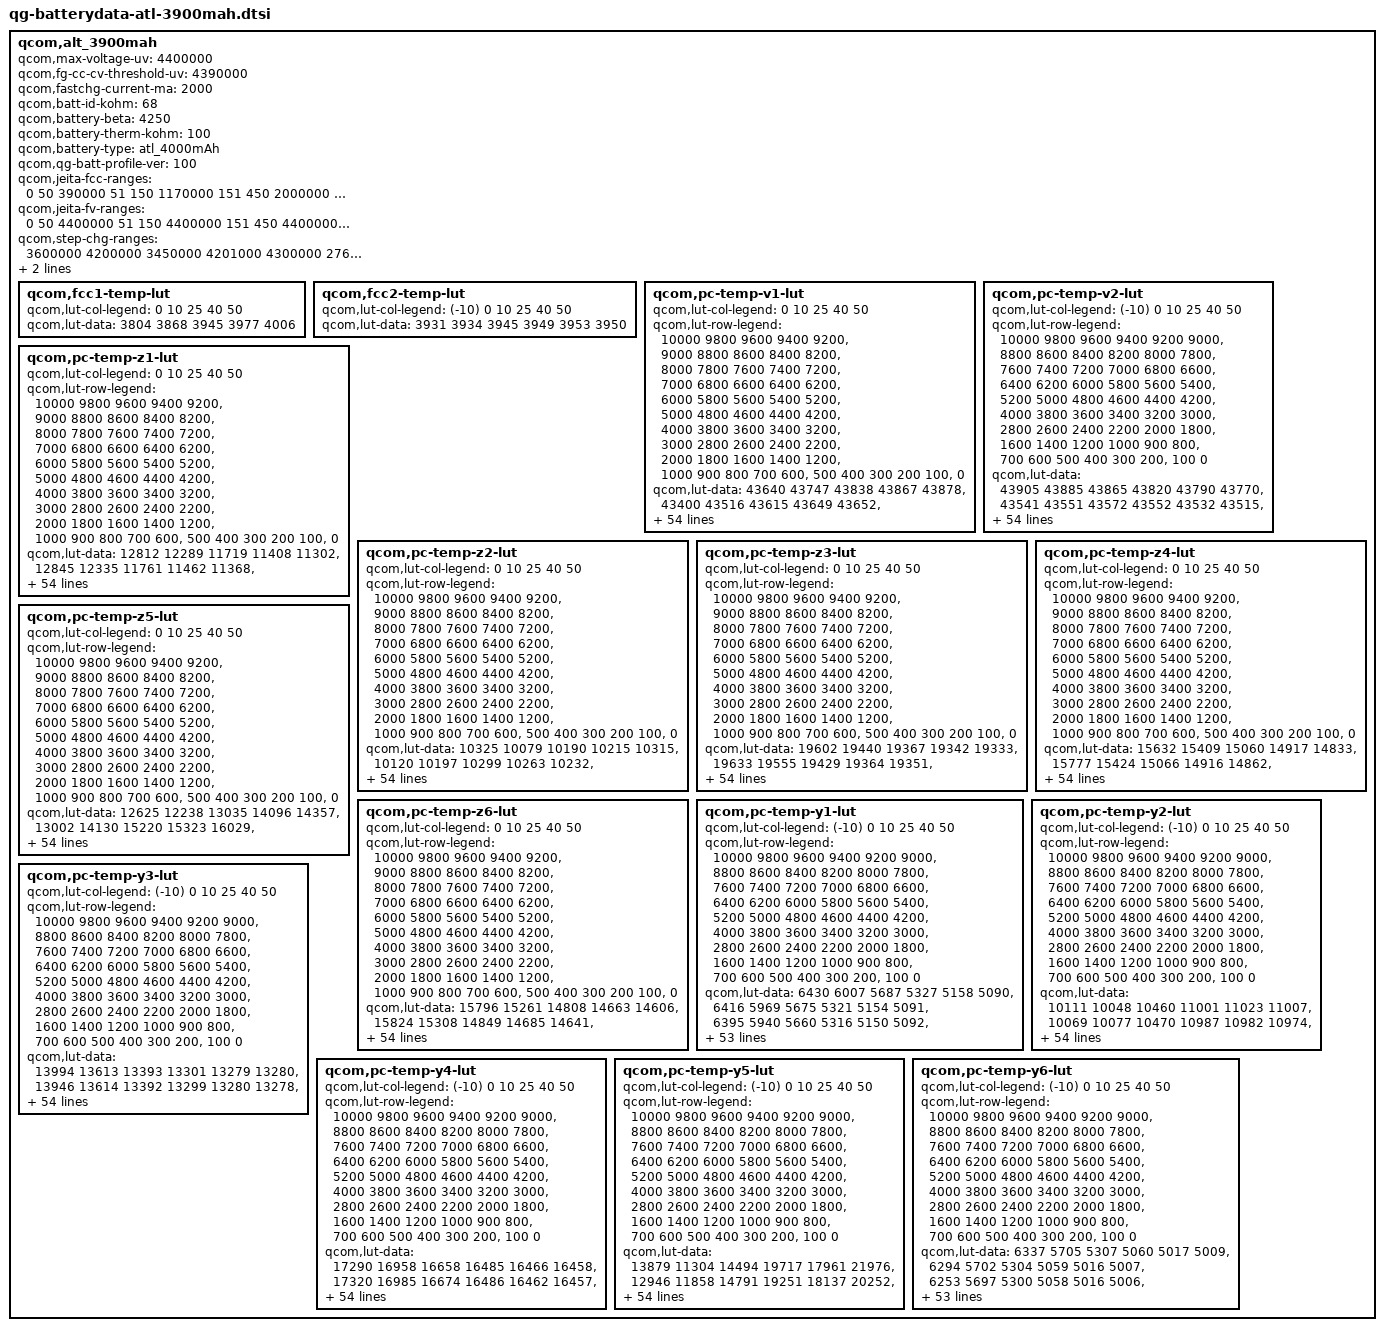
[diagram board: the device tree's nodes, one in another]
qcom,alt_3900mah {
    /* 3668667_LC_M5100_ATL_4000mAH_FG_averaged_MasterSlave_Nov3rd2018 */
    qcom,max-voltage-uv = <4400000>;
    qcom,fg-cc-cv-threshold-uv = <4390000>;
    qcom,fastchg-current-ma = <2000>;
    qcom,batt-id-kohm = <68>;
    qcom,battery-beta = <4250>;
    qcom,battery-therm-kohm = <100>;
    qcom,battery-type = "atl_4000mAh";
    qcom,qg-batt-profile-ver = <100>;

	qcom,jeita-fcc-ranges = <0   50  390000
				51  150  1170000
				151 450  2000000
				451 600  1950000>;
	qcom,jeita-fv-ranges = <0   50  4400000
				51  150  4400000
				151 450  4400000
				451 600  4200000>;
	qcom,step-chg-ranges = <3600000  4200000  3450000
				4201000  4300000  2760000
				4301000  4350000  2070000>;

	/* COOL = 5 DegC, WARM = 45 DegC */
	qcom,jeita-soft-thresholds = <0x5316 0x20B9>;
	/* COLD = 0 DegC, HOT = 60 DegC */
	qcom,jeita-hard-thresholds = <0x58CE 0x14A6>;

	qcom,fcc1-temp-lut {
		qcom,lut-col-legend = <0 10 25 40 50>;
		qcom,lut-data = <3804 3868 3945 3977 4006>;
	};

	qcom,fcc2-temp-lut {
		qcom,lut-col-legend = <(-10) 0 10 25 40 50>;
		qcom,lut-data = <3931 3934 3945 3949 3953 3950>;
	};

	qcom,pc-temp-v1-lut {
		qcom,lut-col-legend = <0 10 25 40 50>;
		qcom,lut-row-legend = <10000 9800 9600 9400 9200>,
			<9000 8800 8600 8400 8200>,
			<8000 7800 7600 7400 7200>,
			<7000 6800 6600 6400 6200>,
			<6000 5800 5600 5400 5200>,
			<5000 4800 4600 4400 4200>,
			<4000 3800 3600 3400 3200>,
			<3000 2800 2600 2400 2200>,
			<2000 1800 1600 1400 1200>,
			<1000 900 800 700 600>,
			<500 400 300 200 100>,
			<0>;
		qcom,lut-data = <43640 43747 43838 43867 43878>,
			<43400 43516 43615 43649 43652>,
			<43154 43279 43388 43427 43431>,
			<42913 43039 43156 43200 43207>,
			<42679 42804 42923 42969 42979>,
			<42450 42570 42689 42737 42749>,
			<42223 42340 42454 42504 42517>,
			<42002 42115 42221 42270 42284>,
			<41785 41894 41993 42040 42053>,
			<41574 41676 41767 41812 41822>,
			<41368 41459 41545 41586 41595>,
			<41177 41251 41325 41365 41372>,
			<41005 41066 41113 41147 41152>,
			<40824 40897 40916 40942 40941>,
			<40588 40706 40725 40744 40736>,
			<40313 40459 40524 40547 40538>,
			<40089 40210 40307 40343 40344>,
			<39929 40028 40109 40146 40157>,
			<39792 39887 39954 39975 39981>,
			<39656 39746 39815 39825 39822>,
			<39528 39596 39641 39657 39653>,
			<39394 39438 39408 39439 39440>,
			<39238 39246 39183 39214 39208>,
			<39068 38982 39001 39032 39021>,
			<38902 38767 38842 38871 38868>,
			<38727 38673 38720 38736 38736>,
			<38579 38611 38628 38627 38621>,
			<38498 38549 38547 38532 38518>,
			<38444 38483 38465 38438 38423>,
			<38398 38420 38386 38347 38331>,
			<38353 38361 38316 38268 38249>,
			<38312 38305 38250 38200 38176>,
			<38273 38255 38192 38139 38110>,
			<38238 38213 38142 38082 38048>,
			<38205 38175 38099 38030 37993>,
			<38175 38138 38056 37979 37936>,
			<38148 38105 38016 37929 37875>,
			<38112 38065 37972 37876 37811>,
			<38050 37999 37906 37806 37733>,
			<37968 37907 37813 37716 37636>,
			<37869 37802 37707 37613 37527>,
			<37742 37679 37587 37494 37399>,
			<37597 37539 37450 37357 37257>,
			<37434 37372 37284 37193 37097>,
			<37306 37234 37148 37060 36981>,
			<37218 37155 37067 36982 36917>,
			<37199 37131 37045 36962 36898>,
			<37185 37112 37027 36945 36888>,
			<37153 37096 37013 36924 36868>,
			<37085 37026 36940 36834 36762>,
			<36809 36738 36634 36510 36423>,
			<36351 36275 36178 36049 35961>,
			<35753 35685 35582 35449 35360>,
			<34935 34863 34761 34626 34532>,
			<33622 33553 33462 33319 33223>,
			<30000 30000 30000 30000 30000>;
	};

	qcom,pc-temp-v2-lut {
		qcom,lut-col-legend = <(-10) 0 10 25 40 50>;
		qcom,lut-row-legend = <10000 9800 9600 9400 9200 9000>,
			<8800 8600 8400 8200 8000 7800>,
			<7600 7400 7200 7000 6800 6600>,
			<6400 6200 6000 5800 5600 5400>,
			<5200 5000 4800 4600 4400 4200>,
			<4000 3800 3600 3400 3200 3000>,
			<2800 2600 2400 2200 2000 1800>,
			<1600 1400 1200 1000 900 800>,
			<700 600 500 400 300 200>,
			<100 0>;
		qcom,lut-data = <43905 43885 43865 43820 43790 43770>,
			<43541 43551 43572 43552 43532 43515>,
			<43205 43240 43295 43293 43281 43266>,
			<42900 42956 43032 43045 43038 43024>,
			<42617 42698 42786 42807 42804 42790>,
			<42365 42450 42545 42572 42571 42557>,
			<42158 42203 42306 42338 42338 42326>,
			<41970 41963 42069 42106 42106 42096>,
			<41750 41725 41838 41877 41877 41868>,
			<41464 41483 41612 41651 41650 41641>,
			<41229 41263 41393 41428 41427 41417>,
			<41128 41092 41184 41211 41207 41199>,
			<41064 40945 40982 40997 40990 40983>,
			<40929 40758 40776 40791 40783 40776>,
			<40498 40498 40561 40589 40585 40574>,
			<40013 40223 40351 40392 40392 40379>,
			<39728 39982 40156 40191 40197 40191>,
			<39511 39755 39969 39992 40006 40011>,
			<39327 39544 39773 39809 39828 39836>,
			<39177 39345 39557 39652 39672 39675>,
			<39035 39161 39342 39488 39508 39507>,
			<38857 38994 39138 39277 39296 39294>,
			<38650 38844 38942 39032 39050 39051>,
			<38489 38685 38770 38831 38850 38852>,
			<38381 38490 38622 38680 38698 38701>,
			<38296 38308 38492 38553 38569 38573>,
			<38222 38205 38381 38438 38454 38457>,
			<38160 38137 38283 38336 38352 38355>,
			<38103 38080 38188 38243 38260 38261>,
			<38048 38028 38084 38157 38174 38173>,
			<37996 37982 37991 38080 38097 38094>,
			<37946 37939 37932 38009 38027 38022>,
			<37897 37901 37890 37945 37964 37958>,
			<37847 37862 37853 37883 37898 37889>,
			<37797 37821 37817 37826 37826 37809>,
			<37746 37779 37780 37770 37749 37720>,
			<37691 37734 37741 37705 37662 37623>,
			<37633 37686 37700 37634 37564 37513>,
			<37568 37629 37649 37557 37470 37411>,
			<37487 37557 37574 37477 37389 37327>,
			<37392 37469 37477 37389 37309 37246>,
			<37296 37365 37365 37283 37207 37146>,
			<37198 37232 37227 37153 37082 37023>,
			<37110 37096 37079 37020 36956 36898>,
			<37035 36962 36933 36906 36849 36791>,
			<36962 36879 36871 36873 36817 36764>,
			<36923 36855 36849 36857 36800 36751>,
			<36874 36830 36818 36830 36785 36733>,
			<36806 36781 36772 36783 36741 36685>,
			<36686 36684 36659 36624 36586 36497>,
			<36438 36431 36366 36240 36198 36104>,
			<35993 35958 35881 35705 35669 35573>,
			<35356 35312 35219 34990 34978 34874>,
			<34447 34409 34304 33953 34016 33912>,
			<33033 33059 32966 32536 32653 32511>,
			<27807 27588 27612 27554 27637 27454>;
	};

	qcom,pc-temp-z1-lut {
		qcom,lut-col-legend = <0 10 25 40 50>;
		qcom,lut-row-legend = <10000 9800 9600 9400 9200>,
			<9000 8800 8600 8400 8200>,
			<8000 7800 7600 7400 7200>,
			<7000 6800 6600 6400 6200>,
			<6000 5800 5600 5400 5200>,
			<5000 4800 4600 4400 4200>,
			<4000 3800 3600 3400 3200>,
			<3000 2800 2600 2400 2200>,
			<2000 1800 1600 1400 1200>,
			<1000 900 800 700 600>,
			<500 400 300 200 100>,
			<0>;
		qcom,lut-data = <12812 12289 11719 11408 11302>,
			<12845 12335 11761 11462 11368>,
			<12871 12332 11774 11493 11399>,
			<12880 12317 11769 11494 11406>,
			<12873 12308 11762 11492 11409>,
			<12860 12301 11753 11489 11410>,
			<12851 12294 11740 11483 11410>,
			<12840 12284 11731 11478 11409>,
			<12834 12272 11725 11477 11408>,
			<12840 12262 11721 11476 11409>,
			<12849 12247 11719 11476 11410>,
			<12842 12234 11718 11476 11409>,
			<12803 12230 11717 11475 11406>,
			<12762 12227 11716 11474 11405>,
			<12741 12225 11715 11472 11405>,
			<12725 12214 11714 11471 11405>,
			<12720 12200 11714 11471 11406>,
			<12721 12197 11714 11472 11407>,
			<12723 12200 11716 11472 11409>,
			<12729 12205 11720 11473 11410>,
			<12753 12211 11722 11474 11410>,
			<12771 12217 11725 11475 11411>,
			<12774 12221 11728 11477 11411>,
			<12776 12226 11731 11478 11411>,
			<12776 12229 11735 11480 11413>,
			<12777 12226 11739 11483 11415>,
			<12780 12221 11745 11486 11419>,
			<12781 12220 11750 11491 11423>,
			<12780 12232 11755 11495 11426>,
			<12779 12246 11758 11499 11429>,
			<12780 12247 11764 11504 11432>,
			<12783 12242 11772 11508 11435>,
			<12786 12241 11780 11512 11438>,
			<12795 12248 11785 11516 11442>,
			<12803 12258 11788 11520 11448>,
			<12802 12266 11792 11524 11454>,
			<12796 12276 11798 11529 11455>,
			<12796 12283 11806 11533 11455>,
			<12803 12287 11814 11537 11457>,
			<12815 12292 11822 11541 11461>,
			<12828 12293 11828 11544 11465>,
			<12846 12301 11831 11548 11467>,
			<12849 12306 11835 11553 11468>,
			<12843 12321 11841 11557 11471>,
			<12838 12324 11852 11561 11473>,
			<12848 12321 11863 11564 11476>,
			<12842 12312 11860 11563 11478>,
			<12856 12314 11864 11567 11477>,
			<12835 12326 11866 11567 11480>,
			<12820 12334 11872 11571 11484>,
			<12868 12331 11873 11578 11487>,
			<12890 12356 11888 11585 11493>,
			<12924 12363 11894 11596 11502>,
			<12942 12388 11914 11607 11511>,
			<12942 12388 11914 11607 11511>,
			<12942 12388 11914 11607 11511>;
	};

	qcom,pc-temp-z2-lut {
		qcom,lut-col-legend = <0 10 25 40 50>;
		qcom,lut-row-legend = <10000 9800 9600 9400 9200>,
			<9000 8800 8600 8400 8200>,
			<8000 7800 7600 7400 7200>,
			<7000 6800 6600 6400 6200>,
			<6000 5800 5600 5400 5200>,
			<5000 4800 4600 4400 4200>,
			<4000 3800 3600 3400 3200>,
			<3000 2800 2600 2400 2200>,
			<2000 1800 1600 1400 1200>,
			<1000 900 800 700 600>,
			<500 400 300 200 100>,
			<0>;
		qcom,lut-data = <10325 10079 10190 10215 10315>,
			<10120 10197 10299 10263 10232>,
			<10127 10198 10341 10298 10325>,
			<10130 10198 10331 10313 10356>,
			<10116 10192 10314 10346 10332>,
			<10096 10171 10299 10360 10297>,
			<10078 10152 10283 10350 10250>,
			<10059 10140 10273 10329 10226>,
			<10048 10130 10266 10277 10237>,
			<10046 10125 10258 10179 10201>,
			<10045 10124 10259 10139 10161>,
			<10049 10126 10272 10152 10163>,
			<10065 10168 10281 10170 10178>,
			<10079 10287 10277 10179 10193>,
			<10075 10345 10269 10187 10209>,
			<10062 10293 10270 10194 10223>,
			<10057 10223 10285 10198 10230>,
			<10075 10218 10299 10203 10237>,
			<10105 10238 10300 10213 10251>,
			<10127 10256 10299 10233 10286>,
			<10147 10268 10320 10267 10321>,
			<10161 10277 10423 10389 10347>,
			<10165 10279 10506 10517 10372>,
			<10169 10269 10450 10494 10388>,
			<10173 10260 10328 10364 10399>,
			<10180 10264 10295 10298 10406>,
			<10187 10277 10367 10339 10407>,
			<10190 10287 10439 10396 10396>,
			<10191 10302 10449 10417 10357>,
			<10193 10315 10451 10425 10249>,
			<10199 10315 10445 10415 10179>,
			<10208 10312 10419 10358 10178>,
			<10217 10310 10395 10291 10183>,
			<10225 10315 10398 10273 10195>,
			<10234 10324 10415 10271 10232>,
			<10246 10333 10433 10278 10277>,
			<10263 10344 10453 10344 10324>,
			<10278 10355 10476 10433 10375>,
			<10290 10371 10502 10464 10410>,
			<10300 10387 10535 10479 10441>,
			<10311 10396 10555 10487 10456>,
			<10323 10400 10566 10474 10424>,
			<10342 10407 10572 10457 10390>,
			<10387 10435 10571 10452 10438>,
			<10663 10579 10603 10465 10436>,
			<10685 10620 10605 10476 10408>,
			<10721 10613 10590 10525 10506>,
			<10828 10609 10555 10480 10409>,
			<10829 10652 10541 10522 10532>,
			<10781 10685 10643 10576 10538>,
			<10848 10763 10615 10381 10233>,
			<10584 10687 10612 10303 10178>,
			<10479 10711 10580 10248 10116>,
			<10293 10670 10478 10202 10089>,
			<10293 10670 10478 10202 10089>,
			<10293 10670 10478 10202 10089>;
	};

	qcom,pc-temp-z3-lut {
		qcom,lut-col-legend = <0 10 25 40 50>;
		qcom,lut-row-legend = <10000 9800 9600 9400 9200>,
			<9000 8800 8600 8400 8200>,
			<8000 7800 7600 7400 7200>,
			<7000 6800 6600 6400 6200>,
			<6000 5800 5600 5400 5200>,
			<5000 4800 4600 4400 4200>,
			<4000 3800 3600 3400 3200>,
			<3000 2800 2600 2400 2200>,
			<2000 1800 1600 1400 1200>,
			<1000 900 800 700 600>,
			<500 400 300 200 100>,
			<0>;
		qcom,lut-data = <19602 19440 19367 19342 19333>,
			<19633 19555 19429 19364 19351>,
			<19721 19595 19459 19380 19365>,
			<19758 19617 19467 19392 19375>,
			<19766 19620 19472 19401 19383>,
			<19770 19620 19474 19406 19387>,
			<19771 19618 19476 19408 19388>,
			<19771 19613 19477 19410 19387>,
			<19770 19604 19472 19407 19385>,
			<19760 19597 19465 19397 19378>,
			<19745 19591 19458 19389 19370>,
			<19733 19585 19452 19383 19367>,
			<19730 19579 19445 19378 19365>,
			<19732 19572 19433 19373 19363>,
			<19736 19570 19419 19367 19359>,
			<19737 19567 19416 19364 19354>,
			<19728 19559 19419 19363 19351>,
			<19704 19549 19422 19363 19348>,
			<19678 19533 19414 19360 19344>,
			<19666 19524 19400 19356 19340>,
			<19657 19529 19400 19354 19337>,
			<19652 19541 19422 19362 19341>,
			<19664 19550 19441 19372 19348>,
			<19692 19559 19433 19368 19347>,
			<19708 19564 19415 19349 19333>,
			<19713 19558 19409 19339 19324>,
			<19716 19546 19409 19347 19337>,
			<19714 19541 19410 19359 19362>,
			<19703 19541 19420 19373 19372>,
			<19691 19543 19442 19394 19376>,
			<19680 19546 19450 19404 19378>,
			<19669 19550 19450 19398 19375>,
			<19660 19553 19450 19388 19368>,
			<19655 19550 19447 19381 19362>,
			<19649 19545 19438 19376 19354>,
			<19643 19541 19431 19372 19349>,
			<19636 19538 19426 19368 19347>,
			<19631 19534 19422 19364 19346>,
			<19628 19530 19418 19361 19345>,
			<19625 19525 19415 19358 19346>,
			<19622 19520 19412 19356 19347>,
			<19614 19515 19411 19355 19350>,
			<19605 19510 19409 19355 19354>,
			<19592 19502 19406 19358 19358>,
			<19507 19468 19393 19353 19352>,
			<19491 19447 19380 19341 19329>,
			<19439 19443 19375 19335 19318>,
			<19381 19443 19379 19335 19328>,
			<19427 19422 19360 19329 19311>,
			<19412 19423 19349 19328 19320>,
			<19421 19411 19360 19352 19348>,
			<19341 19426 19356 19356 19355>,
			<19338 19349 19353 19357 19353>,
			<19335 19345 19359 19358 19357>,
			<19335 19345 19359 19358 19357>,
			<19335 19345 19359 19358 19357>;
	};

	qcom,pc-temp-z4-lut {
		qcom,lut-col-legend = <0 10 25 40 50>;
		qcom,lut-row-legend = <10000 9800 9600 9400 9200>,
			<9000 8800 8600 8400 8200>,
			<8000 7800 7600 7400 7200>,
			<7000 6800 6600 6400 6200>,
			<6000 5800 5600 5400 5200>,
			<5000 4800 4600 4400 4200>,
			<4000 3800 3600 3400 3200>,
			<3000 2800 2600 2400 2200>,
			<2000 1800 1600 1400 1200>,
			<1000 900 800 700 600>,
			<500 400 300 200 100>,
			<0>;
		qcom,lut-data = <15632 15409 15060 14917 14833>,
			<15777 15424 15066 14916 14862>,
			<15633 15341 15063 14912 14859>,
			<15493 15198 15017 14897 14851>,
			<15361 15099 14946 14860 14827>,
			<15243 15023 14897 14828 14801>,
			<15155 14960 14858 14801 14779>,
			<15082 14912 14824 14778 14758>,
			<15027 14873 14792 14763 14745>,
			<14990 14842 14766 14752 14738>,
			<14960 14820 14752 14743 14732>,
			<14925 14800 14742 14736 14726>,
			<14873 14773 14736 14730 14718>,
			<14828 14738 14736 14723 14710>,
			<14814 14723 14737 14715 14703>,
			<14816 14741 14734 14707 14696>,
			<14819 14766 14724 14700 14690>,
			<14814 14766 14712 14693 14684>,
			<14807 14748 14702 14684 14678>,
			<14799 14734 14694 14674 14673>,
			<14788 14728 14695 14671 14670>,
			<14781 14724 14726 14700 14696>,
			<14781 14735 14768 14746 14751>,
			<14781 14820 14811 14786 14786>,
			<14785 14891 14857 14827 14810>,
			<14819 14887 14869 14843 14821>,
			<14855 14868 14856 14826 14800>,
			<14856 14848 14835 14794 14756>,
			<14843 14828 14807 14764 14728>,
			<14829 14807 14770 14727 14709>,
			<14818 14788 14746 14705 14697>,
			<14809 14770 14731 14698 14688>,
			<14799 14758 14722 14693 14682>,
			<14788 14750 14717 14691 14681>,
			<14779 14744 14713 14689 14681>,
			<14770 14740 14712 14689 14682>,
			<14762 14736 14712 14691 14684>,
			<14758 14734 14714 14695 14689>,
			<14755 14740 14719 14701 14693>,
			<14754 14750 14732 14711 14698>,
			<14754 14752 14738 14717 14700>,
			<14754 14747 14729 14711 14695>,
			<14753 14741 14722 14706 14689>,
			<14746 14736 14722 14705 14688>,
			<14731 14711 14707 14696 14681>,
			<14724 14703 14693 14687 14671>,
			<14776 14696 14683 14677 14656>,
			<14832 14690 14667 14657 14648>,
			<14772 14702 14671 14645 14644>,
			<14787 14702 14690 14654 14642>,
			<14787 14729 14706 14660 14648>,
			<14892 14721 14714 14659 14645>,
			<14904 14812 14720 14661 14649>,
			<14920 14820 14716 14662 14646>,
			<14920 14820 14716 14662 14646>,
			<14920 14820 14716 14662 14646>;
	};

	qcom,pc-temp-z5-lut {
		qcom,lut-col-legend = <0 10 25 40 50>;
		qcom,lut-row-legend = <10000 9800 9600 9400 9200>,
			<9000 8800 8600 8400 8200>,
			<8000 7800 7600 7400 7200>,
			<7000 6800 6600 6400 6200>,
			<6000 5800 5600 5400 5200>,
			<5000 4800 4600 4400 4200>,
			<4000 3800 3600 3400 3200>,
			<3000 2800 2600 2400 2200>,
			<2000 1800 1600 1400 1200>,
			<1000 900 800 700 600>,
			<500 400 300 200 100>,
			<0>;
		qcom,lut-data = <12625 12238 13035 14096 14357>,
			<13002 14130 15220 15323 16029>,
			<13976 15158 16420 16316 17065>,
			<14627 15900 16803 17025 17858>,
			<14960 16483 17069 17597 18527>,
			<15247 16985 17492 18119 18905>,
			<15641 17423 18071 18701 19233>,
			<16099 17787 18693 19111 19763>,
			<16389 18115 19494 19174 20067>,
			<16517 18511 20264 19189 19919>,
			<16620 19032 20624 19178 19560>,
			<16848 19497 20949 19092 19655>,
			<18070 20586 21051 19000 20121>,
			<19306 23281 20245 18992 20371>,
			<20400 24634 19003 19035 20567>,
			<22340 23983 18924 19169 20797>,
			<22860 22921 20312 19639 21126>,
			<21565 22519 21361 20381 21697>,
			<20092 21996 21212 21319 22382>,
			<19929 21863 20927 22809 23388>,
			<20498 25452 22445 24814 24351>,
			<21418 31809 35072 28931 25352>,
			<26282 35589 45502 32734 26337>,
			<35986 38151 40174 30663 25437>,
			<41045 39501 27660 21704 19547>,
			<42889 36337 21735 16789 15416>,
			<44010 28866 19686 16491 15904>,
			<42714 25551 18693 16578 17373>,
			<37343 25068 19563 17986 19048>,
			<32610 24892 22353 22461 21359>,
			<29992 25697 25378 25599 23505>,
			<28045 28333 29218 26505 25264>,
			<27498 30425 32356 27184 26672>,
			<27376 31636 33296 28408 27139>,
			<27312 32577 33823 30272 27486>,
			<27276 32927 33957 31164 27656>,
			<27232 33442 33397 30538 27491>,
			<27244 33682 32318 29207 27109>,
			<28397 32948 30501 27301 26285>,
			<29864 31516 27326 24093 24115>,
			<29804 30247 25199 21897 22743>,
			<28445 28836 24440 21106 23373>,
			<28162 27787 23739 20689 24075>,
			<28782 27018 22538 20672 24039>,
			<24553 27697 22719 20116 22479>,
			<23296 25082 22102 18662 18223>,
			<19339 24206 21533 18136 18198>,
			<14035 24481 24029 20176 20415>,
			<16395 19758 19566 21367 18600>,
			<16671 20305 16977 18675 20436>,
			<16359 17833 16233 19207 22133>,
			<12655 18810 15359 19182 23187>,
			<12452 13129 14601 18736 20824>,
			<12183 12816 14801 18161 20446>,
			<12183 12816 14801 18161 20446>,
			<12183 12816 14801 18161 20446>;
	};

	qcom,pc-temp-z6-lut {
		qcom,lut-col-legend = <0 10 25 40 50>;
		qcom,lut-row-legend = <10000 9800 9600 9400 9200>,
			<9000 8800 8600 8400 8200>,
			<8000 7800 7600 7400 7200>,
			<7000 6800 6600 6400 6200>,
			<6000 5800 5600 5400 5200>,
			<5000 4800 4600 4400 4200>,
			<4000 3800 3600 3400 3200>,
			<3000 2800 2600 2400 2200>,
			<2000 1800 1600 1400 1200>,
			<1000 900 800 700 600>,
			<500 400 300 200 100>,
			<0>;
		qcom,lut-data = <15796 15261 14808 14663 14606>,
			<15824 15308 14849 14685 14641>,
			<15753 15270 14862 14697 14652>,
			<15675 15201 14843 14694 14653>,
			<15590 15146 14812 14685 14648>,
			<15508 15098 14791 14674 14640>,
			<15448 15055 14772 14665 14632>,
			<15400 15019 14755 14655 14623>,
			<15358 14987 14737 14645 14615>,
			<15322 14963 14720 14634 14608>,
			<15291 14946 14710 14626 14601>,
			<15258 14929 14702 14620 14596>,
			<15219 14909 14696 14614 14591>,
			<15189 14886 14688 14608 14586>,
			<15175 14877 14681 14601 14581>,
			<15166 14880 14677 14595 14575>,
			<15157 14883 14674 14592 14570>,
			<15142 14879 14671 14588 14566>,
			<15128 14863 14662 14583 14562>,
			<15120 14853 14652 14576 14557>,
			<15115 14854 14652 14573 14554>,
			<15112 14859 14678 14591 14568>,
			<15118 14871 14706 14617 14595>,
			<15134 14913 14721 14630 14607>,
			<15151 14947 14732 14639 14612>,
			<15171 14944 14735 14642 14614>,
			<15187 14932 14730 14638 14612>,
			<15187 14922 14724 14633 14607>,
			<15178 14915 14719 14628 14602>,
			<15169 14908 14715 14625 14597>,
			<15161 14904 14711 14620 14592>,
			<15154 14900 14707 14614 14587>,
			<15147 14897 14703 14608 14582>,
			<15141 14894 14699 14604 14578>,
			<15135 14891 14694 14600 14574>,
			<15131 14890 14692 14598 14572>,
			<15128 14889 14691 14598 14572>,
			<15127 14889 14691 14598 14573>,
			<15130 14892 14692 14598 14574>,
			<15134 14896 14698 14602 14577>,
			<15137 14898 14700 14604 14579>,
			<15140 14897 14697 14602 14578>,
			<15141 14896 14695 14600 14578>,
			<15140 14895 14695 14602 14580>,
			<15103 14878 14685 14596 14575>,
			<15094 14866 14674 14586 14558>,
			<15089 14861 14668 14579 14546>,
			<15084 14859 14662 14570 14548>,
			<15084 14855 14656 14562 14537>,
			<15084 14858 14659 14566 14542>,
			<15099 14869 14675 14584 14561>,
			<15111 14879 14679 14587 14566>,
			<15128 14886 14683 14591 14568>,
			<15152 14900 14690 14595 14573>,
			<15152 14900 14690 14595 14573>,
			<15152 14900 14690 14595 14573>;
	};

	qcom,pc-temp-y1-lut {
		qcom,lut-col-legend = <(-10) 0 10 25 40 50>;
		qcom,lut-row-legend = <10000 9800 9600 9400 9200 9000>,
			<8800 8600 8400 8200 8000 7800>,
			<7600 7400 7200 7000 6800 6600>,
			<6400 6200 6000 5800 5600 5400>,
			<5200 5000 4800 4600 4400 4200>,
			<4000 3800 3600 3400 3200 3000>,
			<2800 2600 2400 2200 2000 1800>,
			<1600 1400 1200 1000 900 800>,
			<700 600 500 400 300 200>,
			<100 0>;
		qcom,lut-data = <6430 6007 5687 5327 5158 5090>,
			<6416 5969 5675 5321 5154 5091>,
			<6395 5940 5660 5316 5150 5092>,
			<6372 5919 5645 5311 5146 5091>,
			<6353 5907 5633 5306 5143 5090>,
			<6342 5903 5627 5303 5140 5089>,
			<6339 5911 5626 5299 5138 5088>,
			<6337 5926 5626 5296 5136 5085>,
			<6339 5928 5627 5294 5134 5085>,
			<6355 5916 5632 5291 5132 5084>,
			<6370 5905 5635 5289 5130 5083>,
			<6366 5905 5632 5289 5129 5083>,
			<6354 5907 5626 5289 5129 5082>,
			<6351 5911 5624 5289 5128 5082>,
			<6363 5923 5624 5286 5126 5081>,
			<6376 5933 5625 5283 5124 5081>,
			<6371 5930 5625 5283 5124 5081>,
			<6355 5921 5623 5285 5126 5081>,
			<6347 5916 5623 5286 5126 5081>,
			<6345 5917 5622 5288 5127 5081>,
			<6344 5918 5622 5290 5127 5081>,
			<6347 5921 5625 5293 5128 5082>,
			<6355 5929 5629 5296 5130 5084>,
			<6359 5933 5632 5298 5131 5085>,
			<6348 5928 5633 5300 5132 5085>,
			<6333 5921 5634 5302 5133 5086>,
			<6328 5918 5637 5305 5135 5086>,
			<6325 5916 5647 5309 5138 5087>,
			<6323 5915 5652 5314 5140 5088>,
			<6318 5913 5654 5319 5145 5090>,
			<6313 5912 5658 5324 5148 5093>,
			<6315 5912 5656 5329 5151 5096>,
			<6331 5914 5651 5335 5153 5100>,
			<6342 5915 5648 5341 5155 5102>,
			<6333 5914 5651 5347 5159 5104>,
			<6317 5913 5657 5353 5163 5106>,
			<6311 5914 5660 5358 5166 5108>,
			<6304 5915 5662 5366 5167 5110>,
			<6298 5916 5664 5370 5169 5111>,
			<6302 5913 5667 5372 5171 5113>,
			<6313 5909 5672 5374 5173 5114>,
			<6317 5906 5677 5376 5175 5115>,
			<6315 5908 5677 5381 5177 5117>,
			<6312 5910 5674 5390 5181 5120>,
			<6309 5908 5669 5404 5186 5124>,
			<6293 5909 5685 5409 5191 5125>,
			<6308 5914 5671 5421 5191 5126>,
			<6324 5924 5674 5412 5191 5121>,
			<6336 5926 5666 5412 5192 5125>,
			<6362 5922 5662 5411 5191 5126>,
			<6342 5926 5663 5423 5195 5127>,
			<6338 5933 5671 5433 5201 5132>,
			<6364 5958 5689 5451 5210 5140>,
			<6402 5963 5710 5483 5220 5148>,
			<6402 5963 5710 5483 5220 5148>,
			<6402 5963 5710 5483 5220 5148>;
	};

	qcom,pc-temp-y2-lut {
		qcom,lut-col-legend = <(-10) 0 10 25 40 50>;
		qcom,lut-row-legend = <10000 9800 9600 9400 9200 9000>,
			<8800 8600 8400 8200 8000 7800>,
			<7600 7400 7200 7000 6800 6600>,
			<6400 6200 6000 5800 5600 5400>,
			<5200 5000 4800 4600 4400 4200>,
			<4000 3800 3600 3400 3200 3000>,
			<2800 2600 2400 2200 2000 1800>,
			<1600 1400 1200 1000 900 800>,
			<700 600 500 400 300 200>,
			<100 0>;
		qcom,lut-data = <10111 10048 10460 11001 11023 11007>,
			<10069 10077 10470 10987 10982 10974>,
			<10057 10113 10480 10965 10938 10944>,
			<10070 10148 10491 10938 10898 10915>,
			<10100 10176 10499 10911 10865 10889>,
			<10142 10188 10505 10887 10845 10866>,
			<10201 10184 10509 10861 10835 10846>,
			<10280 10176 10512 10834 10831 10828>,
			<10354 10191 10513 10829 10831 10817>,
			<10432 10337 10516 10845 10837 10810>,
			<10494 10460 10522 10859 10840 10805>,
			<10525 10449 10543 10861 10828 10807>,
			<10546 10416 10589 10869 10805 10813>,
			<10591 10411 10645 10880 10811 10816>,
			<10744 10498 10727 10904 10883 10815>,
			<10877 10622 10803 10938 10967 10817>,
			<10641 10727 10845 10988 11017 10843>,
			<9973 10834 10877 11059 11060 10911>,
			<9685 10938 10897 11127 11108 10992>,
			<9682 11063 10911 11204 11218 11125>,
			<9680 11154 10925 11256 11310 11228>,
			<9677 11122 10946 11234 11261 11192>,
			<9673 10977 10974 11168 11120 11080>,
			<9671 10840 11008 11142 11053 11036>,
			<9670 10635 11059 11159 11040 11063>,
			<9670 10408 11108 11179 11033 11100>,
			<9669 10237 11132 11191 11066 11124>,
			<9668 9891 11149 11214 11164 11150>,
			<9667 9704 11155 11240 11215 11180>,
			<9666 9697 11150 11268 11218 11221>,
			<9666 9692 11143 11301 11221 11259>,
			<9665 9688 11135 11344 11272 11273>,
			<9664 9683 11123 11399 11405 11278>,
			<9664 9679 11110 11429 11477 11275>,
			<9663 9676 11096 11431 11458 11246>,
			<9663 9673 11075 11423 11418 11207>,
			<9662 9671 11050 11404 11374 11188>,
			<9662 9668 11014 11364 11276 11178>,
			<9662 9666 10971 11327 11218 11170>,
			<9661 9664 10920 11291 11215 11148>,
			<9661 9663 10855 11253 11213 11120>,
			<9660 9662 10752 11222 11207 11117>,
			<9660 9661 10543 11175 11190 11161>,
			<9660 9660 10241 11118 11154 11119>,
			<9659 9659 9799 11054 11081 10962>,
			<9659 9658 9723 11003 10992 10840>,
			<9659 9658 9725 11038 10950 10868>,
			<9659 9658 9707 11038 11065 10876>,
			<9658 9657 9694 11038 11009 10892>,
			<9658 9657 9685 10973 11005 10826>,
			<9657 9656 9676 10912 10880 10820>,
			<9656 9656 9669 10852 10831 10747>,
			<9655 9655 9664 10762 10792 10746>,
			<9652 9654 9659 10695 10756 10568>,
			<9652 9654 9659 10695 10756 10568>,
			<9652 9654 9659 10695 10756 10568>;
	};

	qcom,pc-temp-y3-lut {
		qcom,lut-col-legend = <(-10) 0 10 25 40 50>;
		qcom,lut-row-legend = <10000 9800 9600 9400 9200 9000>,
			<8800 8600 8400 8200 8000 7800>,
			<7600 7400 7200 7000 6800 6600>,
			<6400 6200 6000 5800 5600 5400>,
			<5200 5000 4800 4600 4400 4200>,
			<4000 3800 3600 3400 3200 3000>,
			<2800 2600 2400 2200 2000 1800>,
			<1600 1400 1200 1000 900 800>,
			<700 600 500 400 300 200>,
			<100 0>;
		qcom,lut-data = <13994 13613 13393 13301 13279 13280>,
			<13946 13614 13392 13299 13280 13278>,
			<13891 13613 13392 13298 13281 13277>,
			<13841 13611 13393 13298 13281 13277>,
			<13803 13608 13393 13298 13282 13277>,
			<13786 13604 13393 13298 13283 13277>,
			<13794 13597 13393 13299 13284 13278>,
			<13809 13590 13394 13300 13285 13280>,
			<13798 13589 13393 13301 13286 13282>,
			<13659 13594 13392 13302 13287 13283>,
			<13539 13598 13390 13303 13288 13284>,
			<13538 13561 13391 13304 13288 13285>,
			<13545 13480 13393 13306 13289 13286>,
			<13546 13455 13392 13307 13290 13286>,
			<13532 13475 13381 13308 13294 13286>,
			<13510 13495 13370 13309 13297 13287>,
			<13487 13487 13372 13308 13296 13288>,
			<13461 13458 13377 13306 13295 13290>,
			<13452 13429 13378 13305 13294 13291>,
			<13468 13400 13368 13307 13294 13290>,
			<13485 13376 13356 13308 13293 13289>,
			<13482 13365 13348 13306 13290 13286>,
			<13465 13358 13343 13301 13284 13280>,
			<13455 13353 13337 13298 13282 13278>,
			<13453 13349 13332 13296 13281 13277>,
			<13452 13345 13328 13294 13280 13277>,
			<13457 13336 13325 13294 13280 13277>,
			<13473 13319 13322 13293 13280 13278>,
			<13492 13311 13320 13292 13280 13278>,
			<13509 13316 13316 13292 13280 13277>,
			<13529 13327 13313 13292 13279 13276>,
			<13551 13340 13313 13292 13280 13276>,
			<13576 13359 13315 13293 13281 13276>,
			<13602 13378 13317 13293 13282 13277>,
			<13628 13394 13318 13293 13282 13278>,
			<13655 13410 13319 13294 13282 13278>,
			<13683 13431 13321 13293 13281 13278>,
			<13714 13458 13323 13292 13279 13277>,
			<13746 13490 13324 13292 13278 13276>,
			<13777 13523 13325 13291 13279 13277>,
			<13808 13560 13326 13290 13280 13278>,
			<13841 13602 13327 13290 13280 13279>,
			<13877 13649 13328 13292 13281 13280>,
			<13920 13699 13331 13293 13281 13280>,
			<13973 13750 13345 13294 13282 13277>,
			<14047 13820 13373 13302 13286 13284>,
			<14040 13816 13373 13304 13286 13287>,
			<14030 13824 13381 13306 13294 13289>,
			<14101 13879 13404 13313 13295 13289>,
			<14179 13942 13421 13312 13292 13285>,
			<14270 13998 13436 13310 13288 13285>,
			<14384 14074 13478 13315 13289 13286>,
			<14603 14191 13561 13322 13295 13290>,
			<15148 14349 13707 13334 13302 13295>,
			<15148 14349 13707 13334 13302 13295>,
			<15148 14349 13707 13334 13302 13295>;
	};

	qcom,pc-temp-y4-lut {
		qcom,lut-col-legend = <(-10) 0 10 25 40 50>;
		qcom,lut-row-legend = <10000 9800 9600 9400 9200 9000>,
			<8800 8600 8400 8200 8000 7800>,
			<7600 7400 7200 7000 6800 6600>,
			<6400 6200 6000 5800 5600 5400>,
			<5200 5000 4800 4600 4400 4200>,
			<4000 3800 3600 3400 3200 3000>,
			<2800 2600 2400 2200 2000 1800>,
			<1600 1400 1200 1000 900 800>,
			<700 600 500 400 300 200>,
			<100 0>;
		qcom,lut-data = <17290 16958 16658 16485 16466 16458>,
			<17320 16985 16674 16486 16462 16457>,
			<17335 17003 16687 16487 16460 16456>,
			<17335 17014 16696 16488 16458 16455>,
			<17325 17019 16701 16489 16458 16454>,
			<17308 17020 16703 16491 16458 16454>,
			<17234 17017 16699 16492 16458 16454>,
			<17121 17007 16693 16494 16459 16454>,
			<17111 16989 16691 16497 16461 16455>,
			<17296 16934 16691 16502 16464 16456>,
			<17476 16891 16693 16508 16468 16457>,
			<17523 16996 16699 16512 16473 16459>,
			<17552 17231 16714 16517 16479 16463>,
			<17537 17300 16737 16525 16484 16468>,
			<17248 17154 16787 16543 16487 16475>,
			<16964 16993 16826 16563 16491 16483>,
			<16960 16944 16820 16581 16500 16489>,
			<17000 16917 16793 16599 16513 16494>,
			<17015 16894 16764 16610 16530 16503>,
			<16965 16877 16728 16619 16557 16526>,
			<16887 16859 16691 16624 16578 16546>,
			<16818 16831 16653 16599 16560 16533>,
			<16746 16791 16615 16529 16508 16494>,
			<16716 16743 16593 16492 16478 16471>,
			<16717 16661 16582 16481 16467 16461>,
			<16719 16587 16575 16476 16460 16456>,
			<16719 16587 16569 16477 16461 16456>,
			<16719 16623 16565 16482 16465 16459>,
			<16719 16646 16558 16489 16470 16463>,
			<16719 16647 16539 16495 16479 16471>,
			<16720 16645 16519 16503 16489 16481>,
			<16722 16645 16518 16510 16500 16492>,
			<16724 16645 16526 16517 16510 16503>,
			<16726 16648 16536 16520 16514 16507>,
			<16730 16656 16548 16520 16511 16503>,
			<16736 16668 16562 16519 16504 16496>,
			<16740 16678 16575 16516 16494 16485>,
			<16743 16687 16591 16504 16476 16469>,
			<16744 16693 16598 16496 16467 16461>,
			<16738 16692 16598 16498 16470 16463>,
			<16726 16691 16596 16501 16473 16467>,
			<16720 16687 16596 16503 16473 16467>,
			<16718 16675 16597 16505 16472 16464>,
			<16719 16662 16599 16504 16465 16457>,
			<16740 16651 16606 16498 16453 16447>,
			<16775 16664 16625 16515 16470 16463>,
			<16769 16662 16625 16511 16481 16479>,
			<16763 16669 16644 16525 16499 16507>,
			<16792 16701 16674 16549 16526 16532>,
			<16805 16728 16706 16549 16511 16493>,
			<16792 16723 16697 16520 16466 16458>,
			<16762 16703 16693 16527 16470 16460>,
			<16770 16706 16708 16552 16480 16466>,
			<16908 16740 16755 16607 16529 16520>,
			<16908 16740 16755 16607 16529 16520>,
			<16908 16740 16755 16607 16529 16520>;
	};

	qcom,pc-temp-y5-lut {
		qcom,lut-col-legend = <(-10) 0 10 25 40 50>;
		qcom,lut-row-legend = <10000 9800 9600 9400 9200 9000>,
			<8800 8600 8400 8200 8000 7800>,
			<7600 7400 7200 7000 6800 6600>,
			<6400 6200 6000 5800 5600 5400>,
			<5200 5000 4800 4600 4400 4200>,
			<4000 3800 3600 3400 3200 3000>,
			<2800 2600 2400 2200 2000 1800>,
			<1600 1400 1200 1000 900 800>,
			<700 600 500 400 300 200>,
			<100 0>;
		qcom,lut-data = <13879 11304 14494 19717 17961 21976>,
			<12946 11858 14791 19251 18137 20252>,
			<12515 12476 15214 18560 18215 18971>,
			<12494 13082 15670 17797 18218 18095>,
			<12793 13596 16067 17118 18169 17589>,
			<13323 13942 16312 16677 18091 17418>,
			<15348 14111 16444 16448 17959 17821>,
			<18442 14232 16553 16225 17748 18511>,
			<18872 14444 16580 15931 17491 18612>,
			<15303 14958 16538 15484 17132 18393>,
			<12240 15334 16403 15129 16713 18091>,
			<13572 14884 15715 15038 16152 17719>,
			<16977 13877 14567 15036 15558 17237>,
			<18701 13788 14261 14919 15447 16668>,
			<19334 17034 14763 14328 15828 15831>,
			<19666 20170 15643 13832 16157 15261>,
			<18480 19773 17571 13892 15887 15338>,
			<15201 18164 20599 14184 15234 15575>,
			<13889 17365 21606 14782 15004 15698>,
			<15772 17209 21006 17360 15386 15598>,
			<17896 17131 20361 20249 16024 15568>,
			<17575 17846 20253 21701 17191 16315>,
			<15579 20182 20215 22779 19068 17938>,
			<14017 21308 20136 23061 19785 18789>,
			<13161 19781 19743 22128 19646 19134>,
			<12594 17476 19344 20827 19348 19356>,
			<12518 15920 19837 19914 18858 19167>,
			<12513 13820 21599 18974 17993 18378>,
			<12508 12762 22442 18622 17274 17482>,
			<12557 12830 20658 18628 16673 16286>,
			<12658 13007 18392 18643 16267 15294>,
			<12761 13188 18198 18892 16436 15263>,
			<12921 13596 18680 19813 17258 15632>,
			<13093 13857 18949 20584 18137 16160>,
			<13249 13873 18828 21059 19130 17471>,
			<13425 13882 18640 21380 19934 18860>,
			<13646 13946 18582 21260 19818 19062>,
			<13996 14265 18682 20419 18897 18924>,
			<14281 14530 18722 19448 18114 18765>,
			<14311 14574 18471 18126 17682 18595>,
			<14166 14598 18003 16767 17369 18498>,
			<13973 14589 17485 16372 17306 19124>,
			<13467 14432 16738 16289 17480 21284>,
			<13150 14242 15700 16342 17946 20660>,
			<13032 13874 14217 16498 18662 17174>,
			<13178 13548 14341 16687 16408 17623>,
			<13371 13864 14364 17217 15855 17972>,
			<13550 14116 13865 16577 18229 17333>,
			<13663 13849 14175 17675 17344 16440>,
			<13976 14087 14224 17754 16936 16153>,
			<14164 14030 14234 18264 18109 18566>,
			<13799 13852 14487 19588 18374 19412>,
			<13282 13852 14307 19766 21867 21928>,
			<12449 13854 14380 21165 25470 25772>,
			<12449 13854 14380 21165 25470 25772>,
			<12449 13854 14380 21165 25470 25772>;
	};

	qcom,pc-temp-y6-lut {
		qcom,lut-col-legend = <(-10) 0 10 25 40 50>;
		qcom,lut-row-legend = <10000 9800 9600 9400 9200 9000>,
			<8800 8600 8400 8200 8000 7800>,
			<7600 7400 7200 7000 6800 6600>,
			<6400 6200 6000 5800 5600 5400>,
			<5200 5000 4800 4600 4400 4200>,
			<4000 3800 3600 3400 3200 3000>,
			<2800 2600 2400 2200 2000 1800>,
			<1600 1400 1200 1000 900 800>,
			<700 600 500 400 300 200>,
			<100 0>;
		qcom,lut-data = <6337 5705 5307 5060 5017 5009>,
			<6294 5702 5304 5059 5016 5007>,
			<6253 5697 5300 5058 5016 5006>,
			<6214 5692 5297 5058 5016 5006>,
			<6180 5685 5293 5057 5016 5006>,
			<6152 5678 5289 5057 5016 5006>,
			<6132 5670 5285 5058 5017 5007>,
			<6116 5661 5280 5058 5018 5008>,
			<6094 5651 5276 5060 5019 5010>,
			<6060 5639 5272 5061 5021 5011>,
			<6038 5631 5269 5063 5022 5012>,
			<6047 5637 5270 5065 5024 5013>,
			<6071 5650 5272 5067 5026 5015>,
			<6074 5653 5275 5071 5028 5016>,
			<5999 5635 5280 5076 5031 5019>,
			<5915 5611 5283 5082 5035 5021>,
			<5889 5593 5282 5086 5037 5024>,
			<5873 5577 5279 5090 5040 5026>,
			<5865 5562 5274 5093 5044 5030>,
			<5862 5547 5258 5096 5050 5035>,
			<5859 5535 5238 5099 5056 5040>,
			<5850 5529 5222 5090 5049 5035>,
			<5831 5525 5208 5066 5030 5019>,
			<5823 5521 5200 5054 5019 5010>,
			<5828 5507 5197 5050 5015 5007>,
			<5838 5493 5194 5048 5013 5005>,
			<5849 5495 5195 5048 5013 5005>,
			<5866 5512 5196 5050 5015 5006>,
			<5883 5532 5197 5052 5016 5008>,
			<5900 5553 5195 5054 5019 5009>,
			<5918 5576 5193 5057 5022 5012>,
			<5937 5599 5196 5060 5025 5015>,
			<5958 5623 5208 5064 5030 5019>,
			<5980 5649 5222 5066 5031 5021>,
			<6002 5677 5236 5068 5031 5020>,
			<6025 5706 5251 5069 5029 5018>,
			<6050 5738 5268 5068 5026 5016>,
			<6078 5773 5286 5065 5020 5011>,
			<6105 5810 5304 5064 5017 5008>,
			<6129 5848 5322 5065 5018 5009>,
			<6151 5887 5341 5067 5020 5011>,
			<6177 5927 5364 5069 5021 5012>,
			<6208 5968 5391 5073 5021 5012>,
			<6247 6011 5422 5076 5020 5010>,
			<6301 6058 5458 5079 5018 5007>,
			<6376 6123 5518 5094 5026 5016>,
			<6373 6121 5513 5092 5030 5023>,
			<6370 6131 5535 5098 5040 5033>,
			<6438 6188 5585 5112 5049 5039>,
			<6508 6250 5629 5112 5042 5026>,
			<6583 6298 5668 5106 5027 5016>,
			<6678 6360 5739 5118 5030 5018>,
			<6884 6466 5850 5139 5039 5024>,
			<7436 6625 6012 5175 5059 5045>,
			<7436 6625 6012 5175 5059 5045>,
			<7436 6625 6012 5175 5059 5045>;
	};

};
